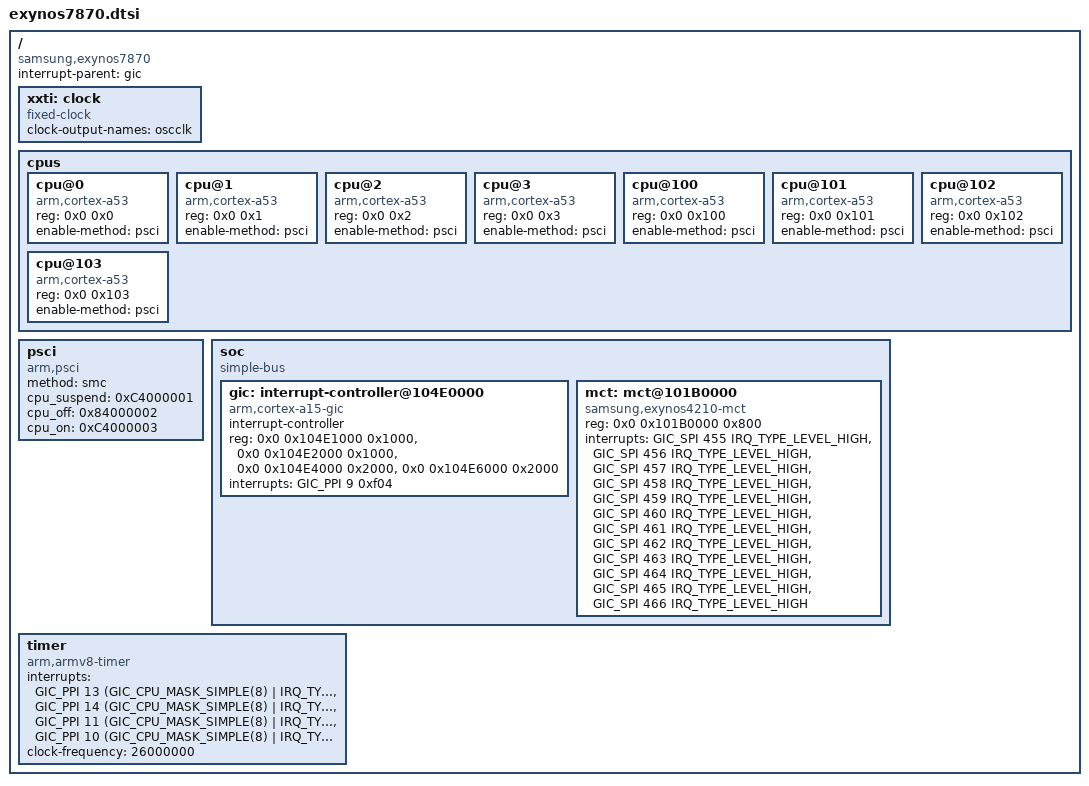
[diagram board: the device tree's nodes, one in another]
/*
 * SAMSUNG EXYNOS7870 SoC device tree source
 *
 * Copyright (c) 2015 Samsung Electronics Co., Ltd.
 *		http://www.samsung.com
 *
 * SAMSUNG EXYNOS7870 SoC device nodes are listed in this file.
 * EXYNOS7870 based board files can include this file and provide
 * values for board specfic bindings.
 *
 * This program is free software; you can redistribute it and/or modify
 * it under the terms of the GNU General Public License version 2 as
 * published by the Free Software Foundation.
 */

/dts-v1/;
#include <dt-bindings/interrupt-controller/arm-gic.h>

/ {
  compatible = "samsung,exynos7870";

	#address-cells = <2>;
	#size-cells = <2>;

	interrupt-parent = <&gic>;

	xxti: clock {
		/* XXTI */
		compatible = "fixed-clock";
		clock-output-names = "oscclk";
		#clock-cells = <0>;
	};

  cpus {
		#address-cells = <1>;
		#size-cells = <0>;

		cpu@0 {
			device_type = "cpu";
			compatible = "arm,cortex-a53", "arm,armv8";
			reg = <0x0 0x0>;
			enable-method = "psci";
		};
		cpu@1 {
			device_type = "cpu";
			compatible = "arm,cortex-a53", "arm,armv8";
			reg = <0x0 0x1>;
			enable-method = "psci";
		};
		cpu@2 {
			device_type = "cpu";
			compatible = "arm,cortex-a53", "arm,armv8";
			reg = <0x0 0x2>;
			enable-method = "psci";
		};
		cpu@3 {
			device_type = "cpu";
			compatible = "arm,cortex-a53", "arm,armv8";
			reg = <0x0 0x3>;
			enable-method = "psci";
		};
		cpu@100 {
			device_type = "cpu";
			compatible = "arm,cortex-a53", "arm,armv8";
			reg = <0x0 0x100>;
			enable-method = "psci";
		};
		cpu@101 {
			device_type = "cpu";
			compatible = "arm,cortex-a53", "arm,armv8";
			reg = <0x0 0x101>;
			enable-method = "psci";
		};
		cpu@102 {
			device_type = "cpu";
			compatible = "arm,cortex-a53", "arm,armv8";
			reg = <0x0 0x102>;
			enable-method = "psci";
		};
		cpu@103 {
			device_type = "cpu";
			compatible = "arm,cortex-a53", "arm,armv8";
			reg = <0x0 0x103>;
			enable-method = "psci";
		};
	};

	psci {
    compatible = "arm,psci";
    method = "smc";
    cpu_suspend = <0xC4000001>;
    cpu_off = <0x84000002>;
    cpu_on = <0xC4000003>;
  };

	soc: soc {
		compatible = "simple-bus";
		#address-cells = <1>;
		#size-cells = <1>;
		ranges = <0 0 0 0x18000000>;

		gic: interrupt-controller@104E0000 {
			compatible = "arm,cortex-a15-gic";
			#interrupt-cells = <3>;
			interrupt-controller;
			reg =	<0x0 0x104E1000 0x1000>,
				<0x0 0x104E2000 0x1000>,
				<0x0 0x104E4000 0x2000>,
				<0x0 0x104E6000 0x2000>;
			interrupts = <GIC_PPI 9 0xf04>;
		};

		mct: mct@101B0000 {
			compatible = "samsung,exynos4210-mct";
			reg = <0x0 0x101B0000 0x800>;
			interrupts = <GIC_SPI 455 IRQ_TYPE_LEVEL_HIGH>,
				<GIC_SPI 456 IRQ_TYPE_LEVEL_HIGH>,
				<GIC_SPI 457 IRQ_TYPE_LEVEL_HIGH>,
				<GIC_SPI 458 IRQ_TYPE_LEVEL_HIGH>,
				<GIC_SPI 459 IRQ_TYPE_LEVEL_HIGH>,
				<GIC_SPI 460 IRQ_TYPE_LEVEL_HIGH>,
				<GIC_SPI 461 IRQ_TYPE_LEVEL_HIGH>,
				<GIC_SPI 462 IRQ_TYPE_LEVEL_HIGH>,
				<GIC_SPI 463 IRQ_TYPE_LEVEL_HIGH>,
				<GIC_SPI 464 IRQ_TYPE_LEVEL_HIGH>,
				<GIC_SPI 465 IRQ_TYPE_LEVEL_HIGH>,
				<GIC_SPI 466 IRQ_TYPE_LEVEL_HIGH>;
		};
	};

	timer: timer {
		compatible = "arm,armv8-timer";
		interrupts = <GIC_PPI 13
				(GIC_CPU_MASK_SIMPLE(8) | IRQ_TYPE_LEVEL_HIGH)>,
			<GIC_PPI 14
				(GIC_CPU_MASK_SIMPLE(8) | IRQ_TYPE_LEVEL_HIGH)>,
			<GIC_PPI 11
				(GIC_CPU_MASK_SIMPLE(8) | IRQ_TYPE_LEVEL_HIGH)>,
			<GIC_PPI 10
				(GIC_CPU_MASK_SIMPLE(8) | IRQ_TYPE_LEVEL_HIGH)>;
		clock-frequency = <26000000>;
	};
}; 
